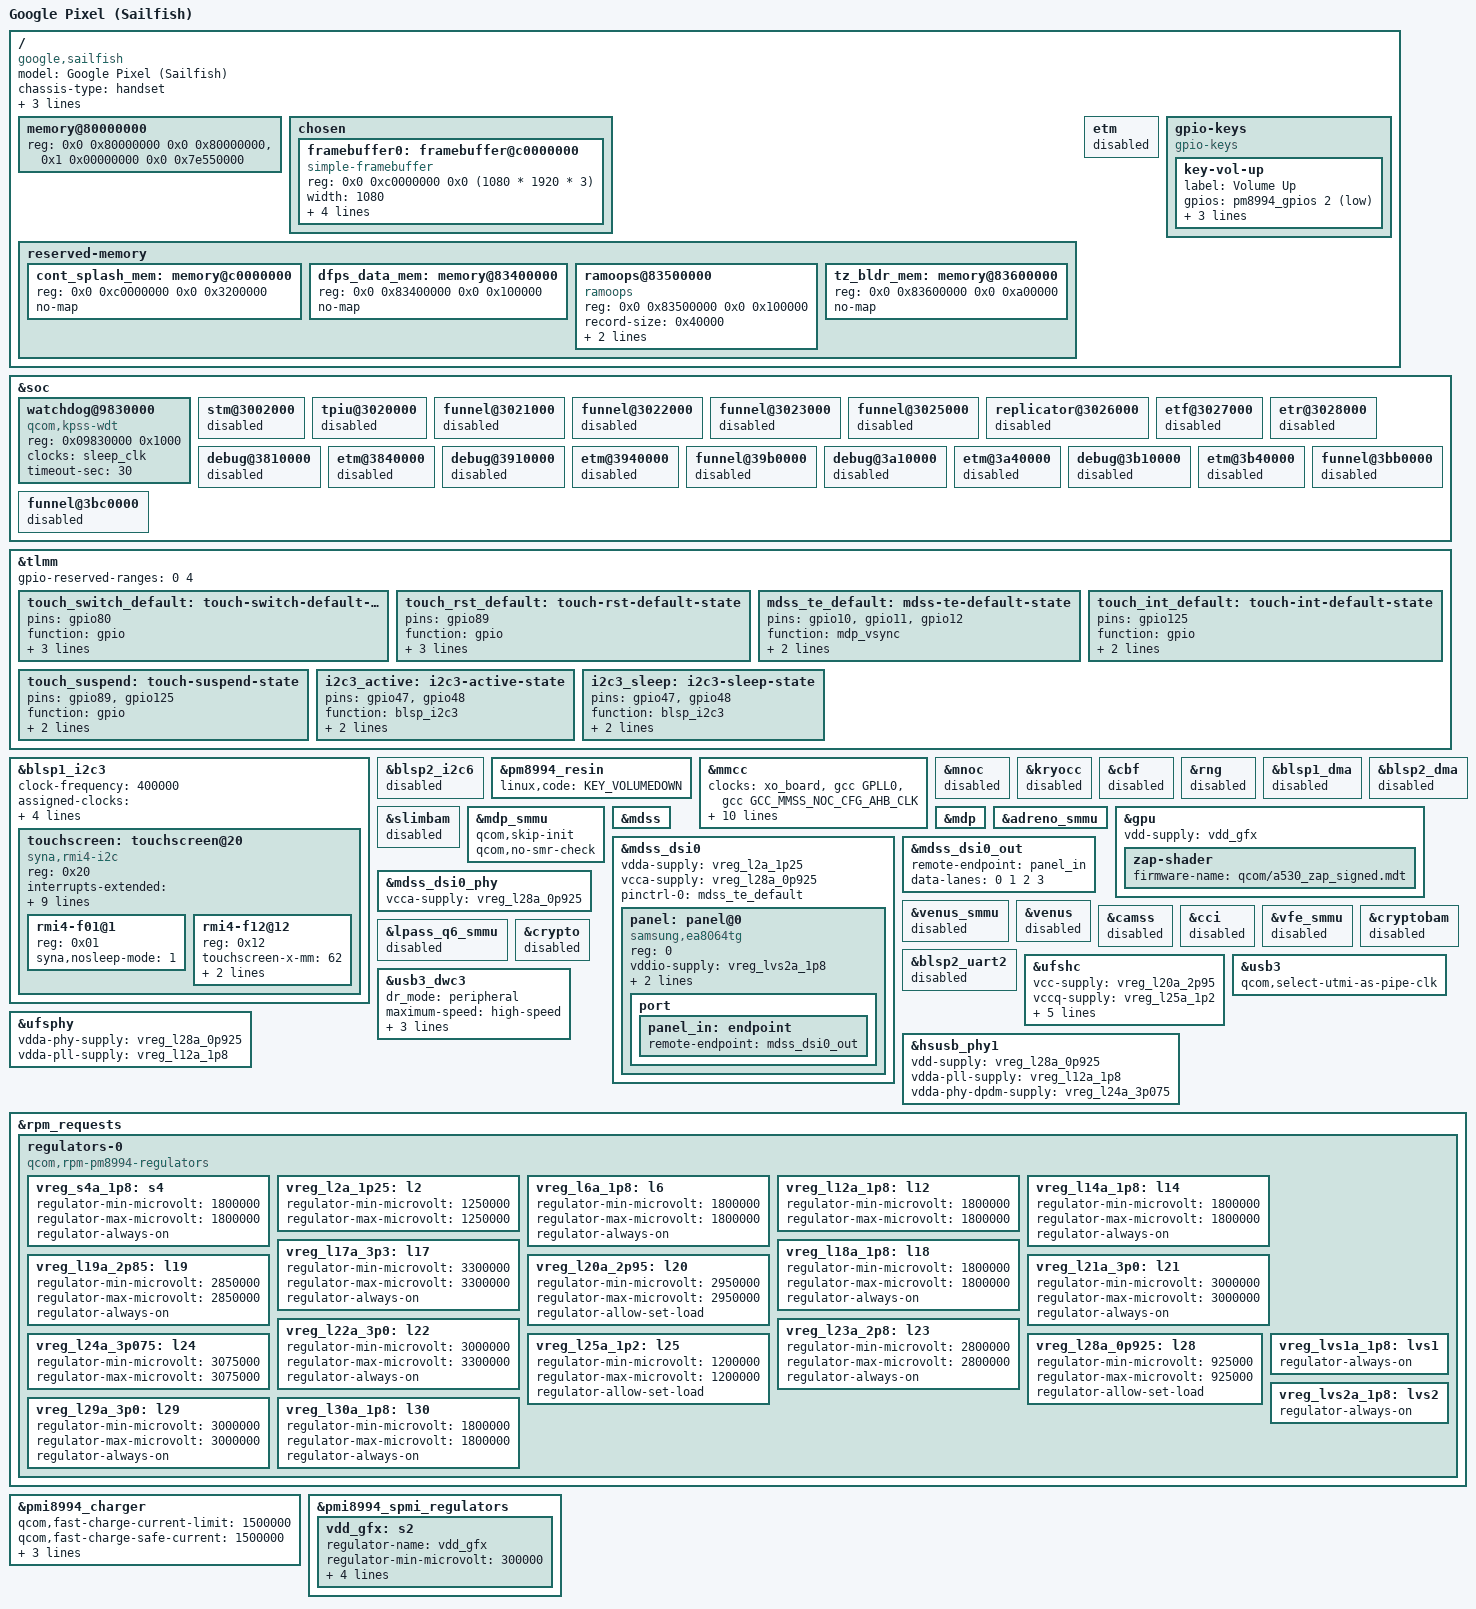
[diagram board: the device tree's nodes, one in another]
// SPDX-License-Identifier: GPL-2.0-only
/*
 * Copyright (c) 2026, Linux Android Porting Team
 * Device Tree Source for Google Pixel (sailfish) - MSM8996 Pro
 */

/dts-v1/;

#include "msm8996pro.dtsi"
#include "pm8994.dtsi"
#include "pmi8994.dtsi"
#include "pmi8996.dtsi"
#include <dt-bindings/input/input.h>
#include <dt-bindings/gpio/gpio.h>
#include <dt-bindings/pinctrl/qcom,pmic-gpio.h>

/ {
	model = "Google Pixel (Sailfish)";
	compatible = "google,sailfish", "qcom,msm8996pro", "qcom,msm8996";
	chassis-type = "handset";
	qcom,msm-id = <420 0x10001>, <421 0x10001>;
	qcom,board-id = <0x80 0>, <3 0>;
	qcom,pmic-id = <0x20009 0x10013 0x0 0x0>;

	/* 4GB LPDDR4 physical memory map */
	memory@80000000 {
		device_type = "memory";
		reg = <0x0 0x80000000 0x0 0x80000000>,
		      <0x1 0x00000000 0x0 0x7e550000>;
	};

	chosen {
		#address-cells = <2>;
		#size-cells = <2>;
		ranges;

		framebuffer0: framebuffer@c0000000 {
			compatible = "simple-framebuffer";
			reg = <0x0 0xc0000000 0x0 (1080 * 1920 * 3)>;
			width = <1080>;
			height = <1920>;
			stride = <(1080 * 3)>;
			format = "r8g8b8";
			memory-region = <&cont_splash_mem>;
		};
	};

	reserved-memory {
		#address-cells = <2>;
		#size-cells = <2>;
		ranges;

		cont_splash_mem: memory@c0000000 {
			reg = <0x0 0xc0000000 0x0 0x3200000>;
			no-map;
		};

		dfps_data_mem: memory@83400000 {
			reg = <0x0 0x83400000 0x0 0x100000>;
			no-map;
		};

		ramoops@83500000 {
			compatible = "ramoops";
			reg = <0x0 0x83500000 0x0 0x100000>;
			record-size = <0x40000>;
			console-size = <0x80000>;
			pmsg-size = <0x40000>;
		};

		tz_bldr_mem: memory@83600000 {
			reg = <0x0 0x83600000 0x0 0xa00000>;
			no-map;
		};
	};

	etm {
		status = "disabled";
	};

	gpio-keys {
		compatible = "gpio-keys";

		key-vol-up {
			label = "Volume Up";
			gpios = <&pm8994_gpios 2 GPIO_ACTIVE_LOW>;
			linux,code = <KEY_VOLUMEUP>;
			wakeup-source;
			debounce-interval = <15>;
		};
	};
};

&soc {
	watchdog@9830000 {
		compatible = "qcom,kpss-wdt";
		reg = <0x09830000 0x1000>;
		clocks = <&sleep_clk>;
		timeout-sec = <30>;
	};

	/* Retail Sailfish TrustZone XPU-locks QDSS/CoreSight debug blocks */
	stm@3002000 { status = "disabled"; };
	tpiu@3020000 { status = "disabled"; };
	funnel@3021000 { status = "disabled"; };
	funnel@3022000 { status = "disabled"; };
	funnel@3023000 { status = "disabled"; };
	funnel@3025000 { status = "disabled"; };
	replicator@3026000 { status = "disabled"; };
	etf@3027000 { status = "disabled"; };
	etr@3028000 { status = "disabled"; };
	debug@3810000 { status = "disabled"; };
	etm@3840000 { status = "disabled"; };
	debug@3910000 { status = "disabled"; };
	etm@3940000 { status = "disabled"; };
	funnel@39b0000 { status = "disabled"; };
	debug@3a10000 { status = "disabled"; };
	etm@3a40000 { status = "disabled"; };
	debug@3b10000 { status = "disabled"; };
	etm@3b40000 { status = "disabled"; };
	funnel@3bb0000 { status = "disabled"; };
	funnel@3bc0000 { status = "disabled"; };
};

&tlmm {
	/* gpio0..3 (blsp_spi1) are XPU-locked by TrustZone for the fingerprint sensor */
	gpio-reserved-ranges = <0 4>;

	touch_switch_default: touch-switch-default-state {
		pins = "gpio80";
		function = "gpio";
		drive-strength = <2>;
		bias-disable;
		output-low;
	};

	touch_rst_default: touch-rst-default-state {
		pins = "gpio89";
		function = "gpio";
		drive-strength = <2>;
		bias-disable;
		output-high;
	};

	/*
	 * Command-mode panel tearing-effect line: route it to the MDP vsync
	 * input. The exact TE gpio is unconfirmed on Sailfish, so all three
	 * mdp_vsync-capable pins (10/11/12, unused here) are muxed as inputs.
	 */
	mdss_te_default: mdss-te-default-state {
		pins = "gpio10", "gpio11", "gpio12";
		function = "mdp_vsync";
		drive-strength = <2>;
		bias-pull-down;
	};

	touch_int_default: touch-int-default-state {
		pins = "gpio125";
		function = "gpio";
		drive-strength = <2>;
		bias-pull-up;
	};

	touch_suspend: touch-suspend-state {
		pins = "gpio89", "gpio125";
		function = "gpio";
		drive-strength = <2>;
		bias-disable;
	};

	i2c3_active: i2c3-active-state {
		pins = "gpio47", "gpio48";
		function = "blsp_i2c3";
		drive-strength = <8>;
		bias-pull-up;
	};

	i2c3_sleep: i2c3-sleep-state {
		pins = "gpio47", "gpio48";
		function = "blsp_i2c3";
		drive-strength = <8>;
		bias-pull-up;
	};
};

&blsp1_i2c3 {
	/delete-property/ dmas;
	/delete-property/ dma-names;
	clock-frequency = <400000>;
	assigned-clocks = <&gcc GCC_BLSP1_QUP3_I2C_APPS_CLK>;
	assigned-clock-rates = <19200000>;
	pinctrl-names = "default", "sleep";
	pinctrl-0 = <&i2c3_active>;
	pinctrl-1 = <&i2c3_sleep>;
	status = "okay";

	touchscreen: touchscreen@20 {
		compatible = "syna,rmi4-i2c";
		reg = <0x20>;
		#address-cells = <1>;
		#size-cells = <0>;
		interrupts-extended = <&tlmm 125 IRQ_TYPE_LEVEL_LOW>;
		reset-gpios = <&tlmm 89 GPIO_ACTIVE_LOW>;
		switch-gpios = <&tlmm 80 GPIO_ACTIVE_HIGH>;
		vdd-supply = <&vreg_l29a_3p0>;
		vio-supply = <&vreg_lvs2a_1p8>;

		pinctrl-names = "default", "sleep";
		pinctrl-0 = <&touch_rst_default &touch_int_default &touch_switch_default>;
		pinctrl-1 = <&touch_suspend>;

		syna,startup-delay-ms = <100>;

		rmi4-f01@1 {
			reg = <0x01>;
			syna,nosleep-mode = <1>;
		};

		rmi4-f12@12 {
			reg = <0x12>;
			touchscreen-x-mm = <62>;
			touchscreen-y-mm = <111>;
			syna,sensor-type = <1>;
		};
	};
};

&blsp2_i2c6 {
	status = "disabled";
};

&pm8994_resin {
	linux,code = <KEY_VOLUMEDOWN>;
	status = "okay";
};

/*
 * Keep native display/MMSS clocks, unused SMMUs, TZ-owned crypto/PRNG,
 * and unused BAM DMA controllers disabled during early bring-up so
 * continuous splash stays intact and TZ XPU regions are untouched.
 */
&mmcc {
	clocks = <&xo_board>,
		 <&gcc GPLL0>,
		 <&gcc GCC_MMSS_NOC_CFG_AHB_CLK>;
	clock-names = "xo",
		      "gpll0",
		      "gcc_mmss_noc_cfg_ahb_clk";
	protected-clocks = <MMSS_MMAGIC_AHB_CLK>,
			   <MMSS_MMAGIC_CFG_AHB_CLK>,
			   <MMSS_MMAGIC_AXI_CLK>,
			   <MMSS_MMAGIC_MAXI_CLK>,
			   <MMAGIC_BIMC_AXI_CLK>,
			   <MMAGIC_BIMC_NOC_CFG_AHB_CLK>,
			   <MMAGIC_CAMSS_AXI_CLK>,
			   <MMAGIC_CAMSS_NOC_CFG_AHB_CLK>,
			   <MMAGIC_VIDEO_AXI_CLK>,
			   <MMAGIC_VIDEO_NOC_CFG_AHB_CLK>;
	/delete-property/ assigned-clocks;
	/delete-property/ assigned-clock-rates;
	status = "okay";
};

&mnoc {
	status = "disabled";
};

/* Keep CPU/CBF clocks at bootloader nominal rate until Kryo voltage regulators are configured */
&kryocc {
	status = "disabled";
};

&cbf {
	status = "disabled";
};

&rng {
	status = "disabled";
};

&blsp1_dma {
	status = "disabled";
};

&blsp2_dma {
	status = "disabled";
};

&slimbam {
	status = "disabled";
};

&mdp_smmu {
	/delete-property/ power-domains;
	qcom,skip-init;
	qcom,no-smr-check;
	status = "okay";
};

&mdss {
	/delete-property/ power-domains;
	status = "okay";
};

&mdp {
	/delete-property/ assigned-clocks;
	/delete-property/ assigned-clock-rates;
	/delete-property/ interconnects;
	/delete-property/ interconnect-names;
	status = "okay";
};

&adreno_smmu {
	/delete-property/ power-domains;
	status = "okay";
};

&gpu {
	/delete-property/ power-domains;
	/delete-property/ interconnects;
	/delete-property/ interconnect-names;
	vdd-supply = <&vdd_gfx>;
	status = "okay";

	zap-shader {
		firmware-name = "qcom/a530_zap_signed.mdt";
	};
};

&mdss_dsi0 {
	/delete-property/ assigned-clocks;
	/delete-property/ assigned-clock-parents;
	vdda-supply = <&vreg_l2a_1p25>;
	vcca-supply = <&vreg_l28a_0p925>;
	pinctrl-names = "default";
	pinctrl-0 = <&mdss_te_default>;
	status = "okay";

	panel: panel@0 {
		compatible = "samsung,ea8064tg";
		reg = <0>;

		vddio-supply = <&vreg_lvs2a_1p8>;
		vci-supply = <&vreg_l29a_3p0>;
		reset-gpios = <&tlmm 39 GPIO_ACTIVE_LOW>;

		port {
			panel_in: endpoint {
				remote-endpoint = <&mdss_dsi0_out>;
			};
		};
	};
};

&mdss_dsi0_out {
	remote-endpoint = <&panel_in>;
	data-lanes = <0 1 2 3>;
};

&mdss_dsi0_phy {
	vcca-supply = <&vreg_l28a_0p925>;
	status = "okay";
};

&venus_smmu {
	status = "disabled";
};

&venus {
	status = "disabled";
};

&camss {
	status = "disabled";
};

&cci {
	status = "disabled";
};

&vfe_smmu {
	status = "disabled";
};

&lpass_q6_smmu {
	status = "disabled";
};

&cryptobam {
	status = "disabled";
};

&crypto {
	status = "disabled";
};

&blsp2_uart2 {
	status = "disabled";
};

&ufshc {
	vcc-supply = <&vreg_l20a_2p95>;
	vccq-supply = <&vreg_l25a_1p2>;
	vccq2-supply = <&vreg_s4a_1p8>;
	vdd-hba-supply = <&vreg_l25a_1p2>;

	vcc-max-microamp = <600000>;
	vccq-max-microamp = <450000>;
	vccq2-max-microamp = <450000>;

	status = "okay";
};

&ufsphy {
	status = "okay";
	vdda-phy-supply = <&vreg_l28a_0p925>;
	vdda-pll-supply = <&vreg_l12a_1p8>;
};

&usb3 {
	status = "okay";
	qcom,select-utmi-as-pipe-clk;
};

&usb3_dwc3 {
	dr_mode = "peripheral";
	maximum-speed = "high-speed";
	phys = <&hsusb_phy1>;
	phy-names = "usb2-phy";
	snps,is-utmi-l1-suspend;
	snps,usb2-gadget-lpm-disable;
};

&hsusb_phy1 {
	status = "okay";
	vdd-supply = <&vreg_l28a_0p925>;
	vdda-pll-supply = <&vreg_l12a_1p8>;
	vdda-phy-dpdm-supply = <&vreg_l24a_3p075>;
};

&rpm_requests {
	regulators-0 {
		compatible = "qcom,rpm-pm8994-regulators";

		vreg_s4a_1p8: s4 {
			regulator-min-microvolt = <1800000>;
			regulator-max-microvolt = <1800000>;
			regulator-always-on;
		};

		vreg_l2a_1p25: l2 {
			regulator-min-microvolt = <1250000>;
			regulator-max-microvolt = <1250000>;
		};

		vreg_l6a_1p8: l6 {
			regulator-min-microvolt = <1800000>;
			regulator-max-microvolt = <1800000>;
			regulator-always-on;
		};

		vreg_l12a_1p8: l12 {
			regulator-min-microvolt = <1800000>;
			regulator-max-microvolt = <1800000>;
		};

		vreg_l14a_1p8: l14 {
			regulator-min-microvolt = <1800000>;
			regulator-max-microvolt = <1800000>;
			regulator-always-on;
		};

		vreg_l17a_3p3: l17 {
			regulator-min-microvolt = <3300000>;
			regulator-max-microvolt = <3300000>;
			regulator-always-on;
		};

		vreg_l18a_1p8: l18 {
			regulator-min-microvolt = <1800000>;
			regulator-max-microvolt = <1800000>;
			regulator-always-on;
		};

		vreg_l19a_2p85: l19 {
			regulator-min-microvolt = <2850000>;
			regulator-max-microvolt = <2850000>;
			regulator-always-on;
		};

		vreg_l20a_2p95: l20 {
			regulator-min-microvolt = <2950000>;
			regulator-max-microvolt = <2950000>;
			regulator-allow-set-load;
		};

		vreg_l21a_3p0: l21 {
			regulator-min-microvolt = <3000000>;
			regulator-max-microvolt = <3000000>;
			regulator-always-on;
		};

		vreg_l22a_3p0: l22 {
			regulator-min-microvolt = <3000000>;
			regulator-max-microvolt = <3300000>;
			regulator-always-on;
		};

		vreg_l23a_2p8: l23 {
			regulator-min-microvolt = <2800000>;
			regulator-max-microvolt = <2800000>;
			regulator-always-on;
		};

		vreg_l24a_3p075: l24 {
			regulator-min-microvolt = <3075000>;
			regulator-max-microvolt = <3075000>;
		};

		vreg_l25a_1p2: l25 {
			regulator-min-microvolt = <1200000>;
			regulator-max-microvolt = <1200000>;
			regulator-allow-set-load;
		};

		vreg_l28a_0p925: l28 {
			regulator-min-microvolt = <925000>;
			regulator-max-microvolt = <925000>;
			regulator-allow-set-load;
		};

		vreg_l29a_3p0: l29 {
			regulator-min-microvolt = <3000000>;
			regulator-max-microvolt = <3000000>;
			regulator-always-on;
		};

		vreg_l30a_1p8: l30 {
			regulator-min-microvolt = <1800000>;
			regulator-max-microvolt = <1800000>;
			regulator-always-on;
		};

		vreg_lvs1a_1p8: lvs1 {
			regulator-always-on;
		};

		vreg_lvs2a_1p8: lvs2 {
			regulator-always-on;
		};
	};
};

&pmi8994_charger {
	qcom,fast-charge-current-limit = <1500000>;
	qcom,fast-charge-safe-current = <1500000>;
	qcom,fast-charge-high-threshold-voltage = <4350000>;
	qcom,fast-charge-safe-voltage = <4350000>;
	status = "okay";
};

&pmi8994_spmi_regulators {
	vdd_gfx: s2 {
		regulator-name = "vdd_gfx";
		regulator-min-microvolt = <300000>;
		regulator-max-microvolt = <1065000>;
		regulator-enable-ramp-delay = <1600>;
		regulator-always-on;
		regulator-boot-on;
	};
};

&mmcc {
	vdd-gfx-supply = <&vdd_gfx>;
};

